# GD32E501 register map
File version: 1.0
CPU: CM33 r0p4, little endian, MPU, FPU, 4 interrupt priority bits
Registers are 32-bit, read-write, reset 0x0 unless marked. A register's access mark holds for its fields unless they carry their own. Offsets are from the block's base; [hi:lo] are bit positions; {n}, {i} and the like mark numbered series.

## MDIO — Management data input/output
Base 0x4000D800
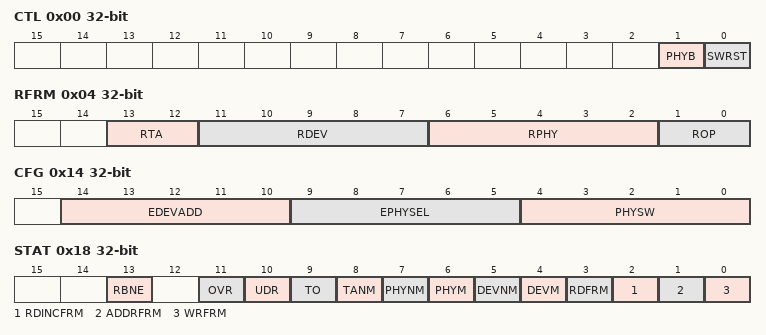
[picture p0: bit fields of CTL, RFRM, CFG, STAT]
0x00 CTL — Control register
  [1] PHYB — MDIO PHY bit length
  [0] SWRST — Software reset
0x04 RFRM — Received frame information register
  [13:12] RTA — Received frame field TA
  [11:7] RDEV — Received frame field DEVADD
  [6:2] RPHY — Received frame field PHYADR
  [1:0] ROP — Received frame field OP
0x08 RDATA read — Received data register
  [15:0] RDATA — Received frame field DATA
0x0C RADDR read — Received address register
  [15:0] RADDR — Received frame field ADDRESS
0x10 TDATA read — Transfer data register
  [15:0] TDATA — Transfer data
0x14 CFG — Configuration register
  [14:10] EDEVADD — Expected DEVADD
  [9:5] EPHYSEL — Selects expected PHYADR
  [4:0] PHYSW — Software provided PHYADR
0x18 STAT read — Status register
  [13] RBNE — Read data buffer not empty flag
  [11] OVR — Receive overrun flag
  [10] UDR — Transmit underrun flag
  [9] TO — Timeout flag
  [8] TANM — Set at end bit of TA of a write data frame or a write address frame
  [7] PHYNM — Set at end bit of PHYADR if PHYADR nonmatches
  [6] PHYM — Set at end bit of PHYADR if PHYADR matches
  [5] DEVNM — Set at end bit of DEVADD if DEVADD nonmatches
  [4] DEVM — Set at end bit of DEVADD if DEVADD matches
  [3] RDFRM — Set at end bit of a read data frame if DEVADD and PHYADR both match
  [2] RDINCFRM — Set at end bit of a post read increment address frame if DEVADD and PHYADR both match
  [1] ADDRFRM — Set at end bit of a write address frame if DEVADD and PHYADR both match
  [0] WRFRM — Set at end bit of a write data frame if DEVADD and PHYADR both match
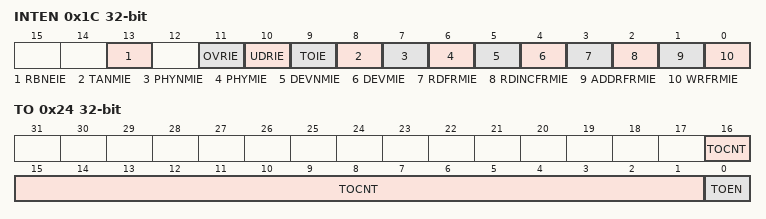
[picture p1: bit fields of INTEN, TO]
0x1C INTEN — Interrupt enable register
  [13] RBNEIE — interrupt is requested when RBDE bit in MDIO_STAT register becomes active
  [11] OVRIE — interrupt is requested when OVR bit in MDIO_STAT register becomes active
  [10] UDRIE — interrupt is requested when UDR bit in MDIO_STAT register becomes active
  [9] TOIE — interrupt is requested when TO bit in MDIO_STAT register becomes active
  [8] TANMIE — interrupt is requested when TANM bit in MDIO_STAT register becomes active
  [7] PHYNMIE — interrupt is requested when PHYNM bit in MDIO_STAT register becomes active
  [6] PHYMIE — interrupt is requested when PHYM bit in MDIO_STAT register becomes active
  [5] DEVNMIE — interrupt is requested when DEVNM bit in MDIO_STAT register becomes active
  [4] DEVMIE — interrupt is requested when DEVM bit in MDIO_STAT register becomes active
  [3] RDFRMIE — interrupt is requested when RDFRM bit in MDIO_STAT register becomes active
  [2] RDINCFRMIE — interrupt is requested when RDINCFRM bit in MDIO_STAT register becomes active
  [1] ADDRFRMIE — interrupt is requested when ADDRFRM bit in MDIO_STAT register becomes active
  [0] WRFRMIE — interrupt is requested when WRFRM bit in MDIO_STAT register becomes active
0x20 PIN read — pin value register
  [4:0] PHYPIN — Pin value read from hardware PRTADR[4:0] pins
0x24 TO read — Timeout register
  [16:1] TOCNT — MDIO time out
  [0] TOEN — Timeout enable

## NVIC — Nested Vectored Interrupt Controller
Base 0xE000E100
{0x0+4i} ISER{i} (i=0..15) — Interrupt Set Enable Register
  [31:0] SETENA
0x80 ICER0 — Interrupt Clear Enable Register
  [31:0] CLRENA
0x84 ICER1 — Interrupt Clear Enable Register
  [31:0] CLRENA
{0x84+4i} ICER{i} (i=2..15) — Interrupt Clear Enable Register
  [31:0] CLRENA
{0x100+4i} ISPR{i} (i=0..15) — Interrupt Set-Pending Register
  [31:0] SETPEND
{0x180+4i} ICPR{i} (i=0..15) — Interrupt Clear-Pending Register
  [31:0] CLRPEND
{0x200+4i} IABR{i} (i=0..15) — Interrupt Active bit Register
  [31:0] IABR
{0x280+4i} ITNS{i} (i=0..15) — Interrupt Active bit Register
  [31:0] ITNS
{0x300+i} IPR{i} 8-bit (i=0..31) — Interrupt Priority Register {i}
  [7:0] PRI_{i:02}
